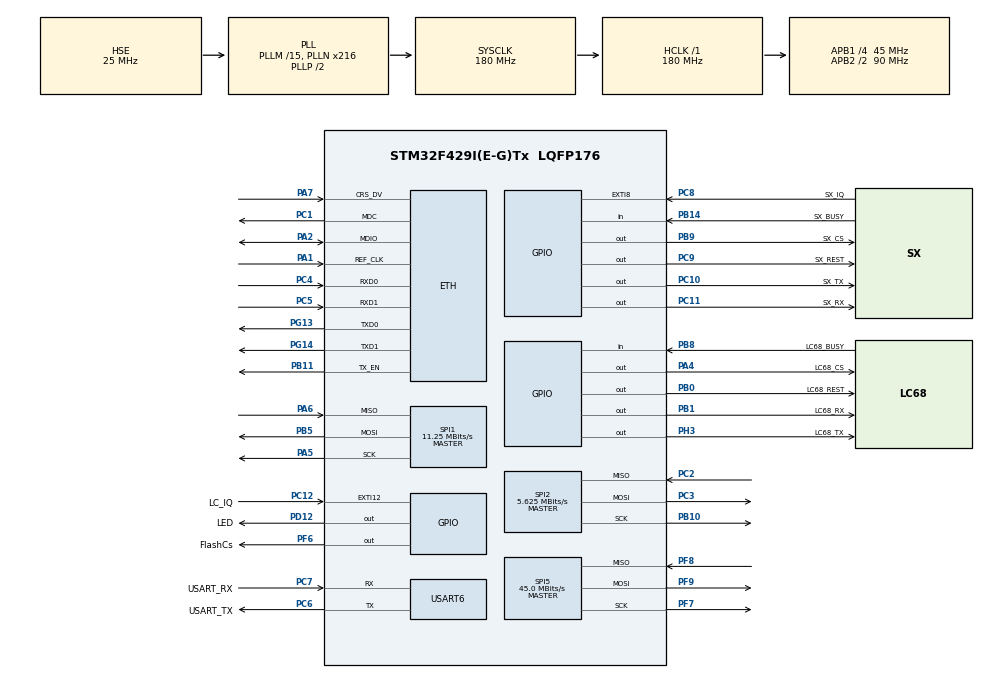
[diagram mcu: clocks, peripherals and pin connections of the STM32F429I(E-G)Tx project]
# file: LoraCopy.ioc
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Dma.Request0=USART6_RX
Dma.Request1=USART6_TX
Dma.USART6_RX.0.Direction=DMA_PERIPH_TO_MEMORY
Dma.USART6_RX.0.FIFOMode=DMA_FIFOMODE_DISABLE
Dma.USART6_RX.0.Instance=DMA2_Stream1
Dma.USART6_RX.0.MemDataAlignment=DMA_MDATAALIGN_BYTE
Dma.USART6_RX.0.MemInc=DMA_MINC_ENABLE
Dma.USART6_RX.0.Mode=DMA_NORMAL
Dma.USART6_RX.0.PeriphDataAlignment=DMA_PDATAALIGN_BYTE
Dma.USART6_RX.0.PeriphInc=DMA_PINC_DISABLE
Dma.USART6_RX.0.Priority=DMA_PRIORITY_LOW
Dma.USART6_TX.1.Direction=DMA_MEMORY_TO_PERIPH
Dma.USART6_TX.1.FIFOMode=DMA_FIFOMODE_DISABLE
Dma.USART6_TX.1.Instance=DMA2_Stream6
Dma.USART6_TX.1.MemDataAlignment=DMA_MDATAALIGN_BYTE
Dma.USART6_TX.1.MemInc=DMA_MINC_ENABLE
Dma.USART6_TX.1.Mode=DMA_NORMAL
Dma.USART6_TX.1.PeriphDataAlignment=DMA_PDATAALIGN_BYTE
Dma.USART6_TX.1.PeriphInc=DMA_PINC_DISABLE
Dma.USART6_TX.1.Priority=DMA_PRIORITY_LOW
ETH.MediaInterface=HAL_ETH_RMII_MODE
FREERTOS.Tasks01=defaultTask,24,128,StartDefaultTask,Default,NULL,Dynamic,NULL,NULL
IWDG.Prescaler=IWDG_PRESCALER_256
IWDG.Reload=625
LWIP.BSP.number=1
LWIP.GATEWAY_ADDRESS=192.168.137.100
LWIP.IP_ADDRESS=192.168.137.100
LWIP.LWIP_DHCP=0
LWIP.NETMASK_ADDRESS=255.255.255.000
LWIP.Version=v2.1.2_Cube
LWIP0.BSP.STBoard=false
LWIP0.BSP.api=BSP_COMPONENT_DRIVER
LWIP0.BSP.component=LAN8742
LWIP0.BSP.instance=LAN8742
LWIP0.BSP.name=Driver_PHY
LWIP0.BSP.semaphore=S_LAN8742
LWIP0.BSP.solution=LAN8742
Mcu.Family=STM32F4
Mcu.Name=STM32F429I(E-G)Tx
Mcu.Package=LQFP176
NVIC.DMA2_Stream1_IRQn=true\:5\:0\:false\:false\:true\:true\:false\:true\:true
NVIC.DMA2_Stream6_IRQn=true\:5\:0\:false\:false\:true\:true\:false\:true\:true
NVIC.ETH_IRQn=true\:5\:0\:false\:false\:true\:true\:true\:true\:true
NVIC.EXTI15_10_IRQn=true\:6\:0\:true\:false\:true\:true\:true\:true\:true
NVIC.EXTI9_5_IRQn=true\:6\:0\:true\:false\:true\:true\:true\:true\:true
NVIC.PriorityGroup=NVIC_PRIORITYGROUP_4
NVIC.TIM1_UP_TIM10_IRQn=true\:15\:0\:false\:false\:true\:false\:false\:true\:true
NVIC.TimeBase=TIM1_UP_TIM10_IRQn
NVIC.TimeBaseIP=TIM1
NVIC.USART6_IRQn=true\:5\:0\:false\:false\:true\:true\:true\:true\:true
PA1.Mode=RMII
PA1.Signal=ETH_REF_CLK
PA13.Mode=Serial_Wire
PA13.Signal=SYS_JTMS-SWDIO
PA14.Mode=Serial_Wire
PA14.Signal=SYS_JTCK-SWCLK
PA2.Mode=RMII
PA2.Signal=ETH_MDIO
PA4.GPIO_Label=LC68_CS
PA4.PinState=GPIO_PIN_SET
PA4.Signal=GPIO_Output
PA5.Mode=Full_Duplex_Master
PA5.Signal=SPI1_SCK
PA6.Mode=Full_Duplex_Master
PA6.Signal=SPI1_MISO
PA7.Mode=RMII
PA7.Signal=ETH_CRS_DV
PB0.GPIO_Label=LC68_REST
PB0.PinState=GPIO_PIN_SET
PB0.Signal=GPIO_Output
PB1.GPIO_Label=LC68_RX
PB1.Signal=GPIO_Output
PB10.Mode=Full_Duplex_Master
PB10.Signal=SPI2_SCK
PB11.Mode=RMII
PB11.Signal=ETH_TX_EN
PB14.GPIO_Label=SX_BUSY
PB14.Signal=GPIO_Input
PB5.Mode=Full_Duplex_Master
PB5.Signal=SPI1_MOSI
PB8.GPIO_Label=LC68_BUSY
PB8.Signal=GPIO_Input
PB9.GPIO_Label=SX_CS
PB9.PinState=GPIO_PIN_SET
PB9.Signal=GPIO_Output
PC1.Mode=RMII
PC1.Signal=ETH_MDC
PC10.GPIO_Label=SX_TX
PC10.Signal=GPIO_Output
PC11.GPIO_Label=SX_RX
PC11.Signal=GPIO_Output
PC12.GPIO_Label=LC_IQ
PC12.Signal=GPXTI12
PC14/OSC32_IN.Mode=LSE-External-Oscillator
PC14/OSC32_IN.Signal=RCC_OSC32_IN
PC15/OSC32_OUT.Mode=LSE-External-Oscillator
PC15/OSC32_OUT.Signal=RCC_OSC32_OUT
PC2.Mode=Full_Duplex_Master
PC2.Signal=SPI2_MISO
PC3.Mode=Full_Duplex_Master
PC3.Signal=SPI2_MOSI
PC4.Mode=RMII
PC4.Signal=ETH_RXD0
PC5.Mode=RMII
PC5.Signal=ETH_RXD1
PC6.GPIO_Label=USART_TX
PC6.Mode=Asynchronous
PC6.Signal=USART6_TX
PC7.GPIO_Label=USART_RX
PC7.Mode=Asynchronous
PC7.Signal=USART6_RX
PC8.GPIO_Label=SX_IQ
PC8.Signal=GPXTI8
PC9.GPIO_Label=SX_REST
PC9.PinState=GPIO_PIN_SET
PC9.Signal=GPIO_Output
PD12.GPIO_Label=LED
PD12.PinState=GPIO_PIN_SET
PD12.Signal=GPIO_Output
PF6.GPIO_Label=FlashCs
PF6.PinState=GPIO_PIN_SET
PF6.Signal=GPIO_Output
PF7.Mode=Full_Duplex_Master
PF7.Signal=SPI5_SCK
PF8.Mode=Full_Duplex_Master
PF8.Signal=SPI5_MISO
PF9.Mode=Full_Duplex_Master
PF9.Signal=SPI5_MOSI
PG13.Mode=RMII
PG13.Signal=ETH_TXD0
PG14.Mode=RMII
PG14.Signal=ETH_TXD1
PH0/OSC_IN.Mode=HSE-External-Oscillator
PH0/OSC_IN.Signal=RCC_OSC_IN
PH1/OSC_OUT.Mode=HSE-External-Oscillator
PH1/OSC_OUT.Signal=RCC_OSC_OUT
PH3.GPIO_Label=LC68_TX
PH3.Signal=GPIO_Output
ProjectManager.HeapSize=0x200
ProjectManager.StackSize=0x400
ProjectManager.TargetToolchain=CMake
RCC.48MHZClocksFreq_Value=90000000
RCC.AHBFreq_Value=180000000
RCC.APB1CLKDivider=RCC_HCLK_DIV4
RCC.APB1Freq_Value=45000000
RCC.APB1TimFreq_Value=90000000
RCC.APB2CLKDivider=RCC_HCLK_DIV2
RCC.APB2Freq_Value=90000000
RCC.APB2TimFreq_Value=180000000
RCC.CortexFreq_Value=180000000
RCC.HCLKFreq_Value=180000000
RCC.HSE_VALUE=25000000
RCC.HSI_VALUE=16000000
RCC.PLLM=15
RCC.PLLN=216
RCC.PLLSourceVirtual=RCC_PLLSOURCE_HSE
RCC.SYSCLKFreq_VALUE=180000000
RCC.SYSCLKSource=RCC_SYSCLKSOURCE_PLLCLK
RCC.VCOOutputFreq_Value=360000000
SPI1.BaudRatePrescaler=SPI_BAUDRATEPRESCALER_8
SPI1.CalculateBaudRate=11.25 MBits/s
SPI1.Direction=SPI_DIRECTION_2LINES
SPI1.Mode=SPI_MODE_MASTER
SPI1.VirtualType=VM_MASTER
SPI2.BaudRatePrescaler=SPI_BAUDRATEPRESCALER_8
SPI2.CLKPolarity=SPI_POLARITY_LOW
SPI2.CalculateBaudRate=5.625 MBits/s
SPI2.Direction=SPI_DIRECTION_2LINES
SPI2.Mode=SPI_MODE_MASTER
SPI2.VirtualType=VM_MASTER
SPI5.CalculateBaudRate=45.0 MBits/s
SPI5.Direction=SPI_DIRECTION_2LINES
SPI5.Mode=SPI_MODE_MASTER
SPI5.VirtualType=VM_MASTER
USART6.VirtualMode=VM_ASYNC
VP_FREERTOS_VS_CMSIS_V2.Mode=CMSIS_V2
VP_IWDG_VS_IWDG.Mode=IWDG_Activate
VP_LWIP_VS_Enabled.Mode=Enabled
VP_SYS_VS_tim1.Mode=TIM1
board=custom

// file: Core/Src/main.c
/* USER CODE BEGIN Header */
/**
  ******************************************************************************
  * @file           : main.c
  * @brief          : Main program body
  ******************************************************************************
  * @attention
  *
  * Copyright (c) 2026 STMicroelectronics.
  * All rights reserved.
  *
  * This software is licensed under terms that can be found in the LICENSE file
  * in the root directory of this software component.
  * If no LICENSE file comes with this software, it is provided AS-IS.
  *
  ******************************************************************************
  */
/* USER CODE END Header */
#include "main.h"
#include "cmsis_os.h"
#include "dma.h"
#include "iwdg.h"
#include "lwip.h"
#include "spi.h"
#include "usart.h"
#include "gpio.h"

void SystemClock_Config(void);
void MX_FREERTOS_Init(void);

int main(void)
{

  /* MCU Configuration--------------------------------------------------------*/

  /* Reset of all peripherals, Initializes the Flash interface and the Systick. */
  HAL_Init();

  /* Configure the system clock */
  SystemClock_Config();

  /* Initialize all configured peripherals */
  MX_GPIO_Init();
  MX_DMA_Init();
  MX_IWDG_Init();
  MX_SPI1_Init();
  MX_SPI2_Init();
  MX_USART6_UART_Init();
  MX_SPI5_Init();
  /* USER CODE BEGIN 2 */
  printf("process is runing\r\n");
  /* USER CODE END 2 */

  /* Init scheduler */
  osKernelInitialize();  /* Call init function for freertos objects (in cmsis_os2.c) */
  MX_FREERTOS_Init();

  /* Start scheduler */
  osKernelStart();

  /* We should never get here as control is now taken by the scheduler */

  /* Infinite loop */
  while (1)
  {

  }
}

void SystemClock_Config(void)
{
  RCC_OscInitTypeDef RCC_OscInitStruct = {0};
  RCC_ClkInitTypeDef RCC_ClkInitStruct = {0};

  /** Configure the main internal regulator output voltage
  */
  __HAL_RCC_PWR_CLK_ENABLE();
  __HAL_PWR_VOLTAGESCALING_CONFIG(PWR_REGULATOR_VOLTAGE_SCALE1);

  /** Initializes the RCC Oscillators according to the specified parameters
  * in the RCC_OscInitTypeDef structure.
  */
  RCC_OscInitStruct.OscillatorType = RCC_OSCILLATORTYPE_LSI|RCC_OSCILLATORTYPE_HSE;
  RCC_OscInitStruct.HSEState = RCC_HSE_ON;
  RCC_OscInitStruct.LSIState = RCC_LSI_ON;
  RCC_OscInitStruct.PLL.PLLState = RCC_PLL_ON;
  RCC_OscInitStruct.PLL.PLLSource = RCC_PLLSOURCE_HSE;
  RCC_OscInitStruct.PLL.PLLM = 15;
  RCC_OscInitStruct.PLL.PLLN = 216;
  RCC_OscInitStruct.PLL.PLLP = RCC_PLLP_DIV2;
  RCC_OscInitStruct.PLL.PLLQ = 4;
  if (HAL_RCC_OscConfig(&RCC_OscInitStruct) != HAL_OK)
  {
    Error_Handler();
  }

  /** Activate the Over-Drive mode
  */
  if (HAL_PWREx_EnableOverDrive() != HAL_OK)
  {
    Error_Handler();
  }

  /** Initializes the CPU, AHB and APB buses clocks
  */
  RCC_ClkInitStruct.ClockType = RCC_CLOCKTYPE_HCLK|RCC_CLOCKTYPE_SYSCLK
                              |RCC_CLOCKTYPE_PCLK1|RCC_CLOCKTYPE_PCLK2;
  RCC_ClkInitStruct.SYSCLKSource = RCC_SYSCLKSOURCE_PLLCLK;
  RCC_ClkInitStruct.AHBCLKDivider = RCC_SYSCLK_DIV1;
  RCC_ClkInitStruct.APB1CLKDivider = RCC_HCLK_DIV4;
  RCC_ClkInitStruct.APB2CLKDivider = RCC_HCLK_DIV2;

  if (HAL_RCC_ClockConfig(&RCC_ClkInitStruct, FLASH_LATENCY_5) != HAL_OK)
  {
    Error_Handler();
  }
}

/* USER CODE BEGIN 4 */
int _write(int fd, char *ptr, int len)
{
  HAL_UART_Transmit(&huart6, (uint8_t *)ptr, len, 0xFFFF);
  return len;
}
/* USER CODE END 4 */

void HAL_TIM_PeriodElapsedCallback(TIM_HandleTypeDef *htim)
{
  if (htim->Instance == TIM1)
  {
    HAL_IncTick();
  }
}

void Error_Handler(void)
{
  __disable_irq();
  while (1)
  {
  }
}

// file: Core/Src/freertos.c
/* USER CODE BEGIN Header */
/**
  ******************************************************************************
  * File Name          : freertos.c
  * Description        : Code for freertos applications
  ******************************************************************************
  * @attention
  *
  * Copyright (c) 2026 STMicroelectronics.
  * All rights reserved.
  *
  * This software is licensed under terms that can be found in the LICENSE file
  * in the root directory of this software component.
  * If no LICENSE file comes with this software, it is provided AS-IS.
  *
  ******************************************************************************
  */
/* USER CODE END Header */

#include "FreeRTOS.h"
#include "task.h"
#include "main.h"
#include "cmsis_os.h"

/* USER CODE BEGIN Includes */
#include "../../App/FreertosTask/FreeRtosHandler.h"
/* USER CODE END Includes */

/* Definitions for defaultTask */
osThreadId_t defaultTaskHandle;
const osThreadAttr_t defaultTask_attributes = {
  .name = "defaultTask",
  .stack_size = 1024 * 4,
  .priority = (osPriority_t) osPriorityNormal,
};

void StartDefaultTask(void *argument);

extern void MX_LWIP_Init(void);
void MX_FREERTOS_Init(void); /* (MISRA C 2004 rule 8.1) */

void MX_FREERTOS_Init(void) {

  /* Create the thread(s) */
  /* creation of defaultTask */
  defaultTaskHandle = osThreadNew(StartDefaultTask, NULL, &defaultTask_attributes);

}

void StartDefaultTask(void *argument)
{
  /* init code for LWIP */
  //MX_LWIP_Init();
  /* USER CODE BEGIN StartDefaultTask */
  CreateWatchDogTask();
  CreateInitAllTask();
  vTaskDelete(NULL);
  /* Infinite loop */

  /* USER CODE END StartDefaultTask */
}
